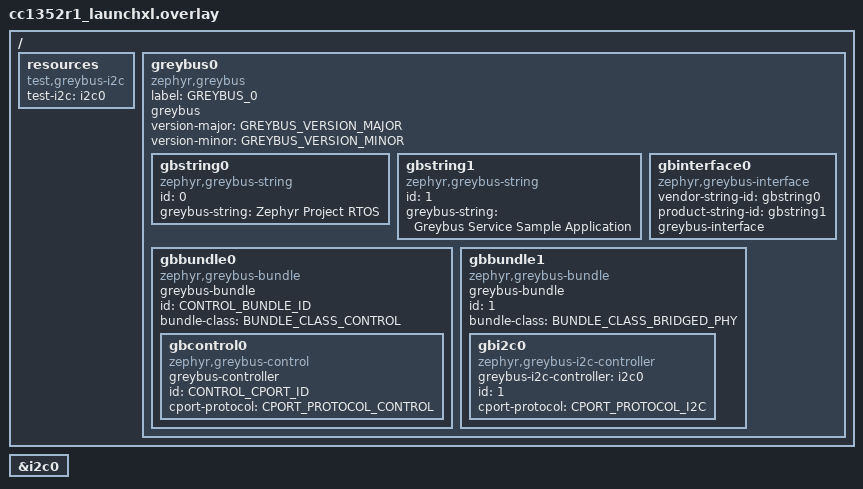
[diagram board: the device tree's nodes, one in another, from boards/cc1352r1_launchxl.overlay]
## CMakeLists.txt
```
# SPDX-License-Identifier: BSD-3-Clause

zephyr_include_directories(../../../include)

cmake_minimum_required(VERSION 3.13.1)
find_package(Zephyr REQUIRED HINTS $ENV{ZEPHYR_BASE})
project(greybus)

FILE(GLOB_RECURSE app_sources src/*.c)
target_sources(app PRIVATE ${app_sources})
```

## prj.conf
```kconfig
CONFIG_ZTEST=y

#CONFIG_REQUIRES_FULL_LIBC=y
#CONFIG_NEWLIB_LIBC=y
#CONFIG_GPIO=y
CONFIG_GREYBUS=y
#CONFIG_GB_LOG_LEVEL=4
#CONFIG_GREYBUS_AUDIO=y
#CONFIG_GREYBUS_CAMERA=y
CONFIG_GREYBUS_CONTROL=y
#CONFIG_GREYBUS_GPIO=y
#CONFIG_GREYBUS_DEBUG=y
#CONFIG_GREYBUS_HID=y
CONFIG_GREYBUS_I2C=y
#CONFIG_GREYBUS_LIGHTS=y
#CONFIG_GREYBUS_LOOPBACK=y
#CONFIG_GREYBUS_POWER_SUPPLY=y
#CONFIG_GREYBUS_PWM=y
#CONFIG_GREYBUS_SDIO=y
#CONFIG_GREYBUS_SPI=y
#CONFIG_GREYBUS_UART=y
#CONFIG_GREYBUS_USB=y
#CONFIG_GREYBUS_VIBRATOR=y
CONFIG_CONSOLE_SUBSYS=y
#CONFIG_CONSOLE_GETCHAR=y
CONFIG_NO_OPTIMIZATIONS=y
CONFIG_MINIMAL_LIBC_MALLOC_ARENA_SIZE=16384
#CONFIG_MINIMAL_LIBC_MALLOC_ARENA_SIZE=32768
# Generic networking options
CONFIG_NETWORKING=y
CONFIG_NET_UDP=y
CONFIG_NET_TCP=y
CONFIG_NET_IPV6=y
CONFIG_NET_IPV4=y
CONFIG_NET_SOCKETS=y
CONFIG_NET_SOCKETS_POSIX_NAMES=y
CONFIG_POSIX_MAX_FDS=32

# Kernel options
CONFIG_MAIN_STACK_SIZE=1024
#CONFIG_ENTROPY_GENERATOR=y
CONFIG_TEST_RANDOM_GENERATOR=y
CONFIG_INIT_STACKS=y

# Logging
CONFIG_NET_LOG=y
CONFIG_LOG=y
CONFIG_NET_STATISTICS=y
CONFIG_PRINTK=y

# Network buffers
CONFIG_NET_PKT_RX_COUNT=4
CONFIG_NET_PKT_TX_COUNT=4
CONFIG_NET_BUF_RX_COUNT=16
CONFIG_NET_BUF_TX_COUNT=16
CONFIG_NET_CONTEXT_NET_PKT_POOL=y

# IP address options
CONFIG_NET_IF_UNICAST_IPV6_ADDR_COUNT=3
CONFIG_NET_IF_MCAST_IPV6_ADDR_COUNT=4
CONFIG_NET_MAX_CONTEXTS=10

# Network shell
CONFIG_NET_SHELL=y
CONFIG_SHELL=y

# Network application options and configuration
CONFIG_NET_CONFIG_SETTINGS=y
CONFIG_NET_CONFIG_MY_IPV6_ADDR="2001:db8::1"
CONFIG_NET_CONFIG_PEER_IPV6_ADDR="2001:db8::2"
CONFIG_NET_CONFIG_MY_IPV4_ADDR="192.0.2.1"
CONFIG_NET_CONFIG_PEER_IPV4_ADDR="192.0.2.2"

# How many client can connect to echo-server simultaneously
#CONFIG_NET_SAMPLE_NUM_HANDLERS=1

# Temporary until automatic thread stack allocation is available
CONFIG_PTHREAD_DYNAMIC_STACK=y
CONFIG_PTHREAD_DYNAMIC_STACK_RESERVED_COUNT=8
```

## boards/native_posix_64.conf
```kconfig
# Copyright (c) 2020 Friedt Professional Engineering Services, Inc
# SPDX-License-Identifier: BSD-3-Clause

CONFIG_GPIO_SIM=y
```

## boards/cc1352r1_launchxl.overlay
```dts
/*
 * Copyright (c) 2020 Friedt Professional Engineering Services, Inc
 *
 * SPDX-License-Identifier: BSD-3-Clause
 */
 #include <dt-bindings/greybus/greybus.h>

/ {
	resources {
		compatible = "test,greybus-i2c";
		test-i2c = <&i2c0>; 
	};

	greybus0: greybus0 {
		compatible = "zephyr,greybus";
		label = "GREYBUS_0";
		greybus;
	};
};

&i2c0 {
	status = "okay";
};

&greybus0 {
	status = "okay";
	/* defaults in effect, so this isn't necessary */
	version-major = <GREYBUS_VERSION_MAJOR>;
	version-minor = <GREYBUS_VERSION_MINOR>;

	gbstring0: gbstring0 {
		status = "okay";
		compatible = "zephyr,greybus-string";
		id = <0>;
		greybus-string = "Zephyr Project RTOS";
	};

	gbstring1: gbstring1 {
		status = "okay";
		compatible = "zephyr,greybus-string";
		id = <1>;
		greybus-string = "Greybus Service Sample Application";
	};

	gbinterface0 {
		status = "okay";
		compatible = "zephyr,greybus-interface";
		vendor-string-id = <&gbstring0>;
		product-string-id = <&gbstring1>;
		greybus-interface;
	};

	gbbundle0 {
		status = "okay";
		compatible = "zephyr,greybus-bundle";
		greybus-bundle;
		/* Control Bundle 0
		 * Note: control bundle 0 and control cport 0 are optional
		 * Since instance numbers automatically begin at 0, the id
		 * is a mandatory field for bundles and cports.
		 */
		id = <CONTROL_BUNDLE_ID>;
		bundle-class = <BUNDLE_CLASS_CONTROL>;

		gbcontrol0 {
			status = "okay";
			compatible = "zephyr,greybus-control";
			greybus-controller;
			/* Control CPort 0
			 * Note: control bundle 0 and control cport 0 are optional
			 * Since instance numbers automatically begin at 0, the id
			 * is a mandatory field for bundles and cports.
			 */
			id = <CONTROL_CPORT_ID>;
			cport-protocol = <CPORT_PROTOCOL_CONTROL>; 
		};
	};
	
	gbbundle1 {
		status = "okay";
		compatible = "zephyr,greybus-bundle";
		greybus-bundle;
		id = <1>;
		bundle-class = <BUNDLE_CLASS_BRIDGED_PHY>;		
				
		gbi2c0 {
			status = "okay";
			compatible = "zephyr,greybus-i2c-controller";
			greybus-i2c-controller = <&i2c0>;
			id = <1>;
			cport-protocol = <CPORT_PROTOCOL_I2C>;
		};
	};
};
```

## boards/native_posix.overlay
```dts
/*
 * Copyright (c) 2020 Friedt Professional Engineering Services, Inc
 *
 * SPDX-License-Identifier: BSD-3-Clause
 */
 #include <dt-bindings/greybus/greybus.h>

/ {
	resources {
		compatible = "test,greybus-i2c";
		test-i2c = <&i2c0>; 
	};

	greybus0: greybus0 {
		compatible = "zephyr,greybus";
		label = "GREYBUS_0";
		greybus;
	};
};

&i2c0 {
	status = "okay";
};

&greybus0 {
	label = "GREYBUS_0";
	status = "okay";
	/* defaults in effect, so this isn't necessary */
	version-major = <GREYBUS_VERSION_MAJOR>;
	version-minor = <GREYBUS_VERSION_MINOR>;

	gbstring0: gbstring0 {
		label = "GBSTRING_0";
		status = "okay";
		compatible = "zephyr,greybus-string";
		id = <0>;
		greybus-string = "Zephyr Project RTOS";
	};

	gbstring1: gbstring1 {
		label = "GBSTRING_1";
		status = "okay";
		compatible = "zephyr,greybus-string";
		id = <1>;
		greybus-string = "Greybus Service Sample Application";
	};

	gbinterface0 {
		label = "GBINTERFACE_0";
		status = "okay";
		compatible = "zephyr,greybus-interface";
		vendor-string-id = <&gbstring0>;
		product-string-id = <&gbstring1>;
		greybus-interface;
	};

	gbbundle0 {
		label = "GBBUNDLE_0";
		status = "okay";
		compatible = "zephyr,greybus-bundle";
		greybus-bundle;
		/* Control Bundle 0
		 * Note: control bundle 0 and control cport 0 are optional
		 * Since instance numbers automatically begin at 0, the id
		 * is a mandatory field for bundles and cports.
		 */
		id = <CONTROL_BUNDLE_ID>;
		bundle-class = <BUNDLE_CLASS_CONTROL>;

		gbcontrol0 {
			label = "GBCONTROL_0";
			status = "okay";
			compatible = "zephyr,greybus-control";
			greybus-controller;
			/* Control CPort 0
			 * Note: control bundle 0 and control cport 0 are optional
			 * Since instance numbers automatically begin at 0, the id
			 * is a mandatory field for bundles and cports.
			 */
			id = <CONTROL_CPORT_ID>;
			cport-protocol = <CPORT_PROTOCOL_CONTROL>; 
		};
	};
	
	gbbundle1 {
		label = "GBBUNDLE_1";
		status = "okay";
		compatible = "zephyr,greybus-bundle";
		greybus-bundle;
		id = <1>;
		bundle-class = <BUNDLE_CLASS_BRIDGED_PHY>;		
				
		gbi2c0 {
			label = "GBI2C_0";
			status = "okay";
			compatible = "zephyr,greybus-i2c-controller";
			greybus-i2c-controller = <&i2c0>;
			id = <1>;
			cport-protocol = <CPORT_PROTOCOL_I2C>;
		};
	};
};
```

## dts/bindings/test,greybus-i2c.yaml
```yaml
#
# Copyright (c) 2020 Friedt Professional Engineering Services, Inc
#
# SPDX-License-Identifier: BSD-3-Clause
#

description: |
    This binding provides resources required to build and run the
    i2c-related tests under tests/subsys/greybus test in Zephyr.

compatible: "test,greybus-i2c"

properties:
    test-i2c:
        type: phandle
        required: true
        description: |
          Identity of an I2C device that will be used with Greybus.
```

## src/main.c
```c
/*
 * Copyright (c) 2020 Friedt Professional Engineering Services, Inc
 *
 * SPDX-License-Identifier: BSD-3-Clause
 */

#include <ztest.h>

extern void test_greybus_i2c_protocol_version(void);
extern void test_greybus_i2c_cport_shutdown(void);
extern void test_greybus_i2c_functionality(void);
extern void test_greybus_i2c_transfer(void);

static void board_setup(void)
{
	if (IS_ENABLED(CONFIG_I2C_SIM)) {
		extern void i2c_sim_setup(void);
		i2c_sim_setup();
	}
}

extern void test_greybus_setup(void);
extern void test_greybus_teardown(void);

void test_main(void) {

	board_setup();
	test_greybus_setup();
    ztest_test_suite(greybus_i2c,
        ztest_unit_test(test_greybus_i2c_protocol_version),
        ztest_unit_test(test_greybus_i2c_cport_shutdown),
        ztest_unit_test(test_greybus_i2c_functionality),
        ztest_unit_test(test_greybus_i2c_transfer)
        );
    ztest_run_test_suite(greybus_i2c);
    test_greybus_teardown();
}
```

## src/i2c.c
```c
/*
 * Copyright (c) 2020 Friedt Professional Engineering Services, Inc
 *
 * SPDX-License-Identifier: BSD-3-Clause
 */

#include <device.h>
#include <errno.h>
#include <greybus/greybus.h>
#include <string.h>
#include <sys/util.h>
#include <ztest.h>
#include <zephyr.h>

#if defined(CONFIG_BOARD_NATIVE_POSIX_64BIT) ||                                \
	defined(CONFIG_BOARD_NATIVE_POSIX_32BIT) ||                            \
	defined(CONFIG_BOARD_NRF52_BSIM)

#include <arpa/inet.h>
#include <netinet/in.h>
#include <poll.h>
#include <sys/byteorder.h>
#include <sys/types.h>
#include <sys/socket.h>
#include <unistd.h>

#else

#include <net/socket.h>
#include <posix/unistd.h>

#undef perror
#define perror(s) LOG_ERR("%s", s)

#endif

#include "../../../../subsys/greybus/i2c-gb.h"

#include "test-greybus-i2c.h"

#define TIMEOUT_MS 1000
#define PORT 4243

static struct device *i2c_dev;

static int fd = -1;

void test_greybus_setup(void)
{
	struct sockaddr_in6 addr = {
		.sin6_family = AF_INET6,
		.sin6_addr = in6addr_loopback,
		.sin6_port = htons(PORT),
	};
	socklen_t addrlen = sizeof(addr);
	int r;

	i2c_dev = device_get_binding(I2C_DEV_NAME);
	zassert_not_equal(i2c_dev, NULL,
			  "failed to get device binding for " I2C_DEV_NAME);

	r = socket(AF_INET6, SOCK_STREAM, 0);
	__ASSERT(r >= 0, "connect: %d", errno);
	fd = r;

	r = connect(fd, (const struct sockaddr *)&addr, addrlen);
	__ASSERT(r == 0, "connect: %d", errno);
}

void test_greybus_teardown(void)
{
	if (fd != -1) {
		close(fd);
		fd = -1;
	}
}

static void tx_rx(const struct gb_operation_hdr *req,
		  struct gb_operation_hdr *rsp, size_t rsp_size)
{
	int r;
	int size;
	struct pollfd pollfd;
	const size_t hdr_size = sizeof(struct gb_operation_hdr);

	size = sys_le16_to_cpu(req->size);
	r = send(fd, req, size, 0);
	zassert_not_equal(r, -1, "send: %s", errno);
	zassert_equal(r, size, "write: expected: %d actual: %d", size, r);

	pollfd.fd = fd;
	pollfd.events = POLLIN;

	r = poll(&pollfd, 1, TIMEOUT_MS);
	zassert_not_equal(r, -1, "poll: %s", errno);
	zassert_not_equal(r, 0, "timeout waiting for response");
	zassert_equal(r, 1, "invalid number of pollfds with data: %d", r);

	r = recv(fd, rsp, hdr_size, 0);
	zassert_not_equal(r, -1, "recv: %s", errno);
	zassert_equal(hdr_size, r, "recv: expected: %u actual: %u",
		      (unsigned)hdr_size, r);

	zassert_equal(rsp->id, req->id,
			  "expected: 0x%04x actual: 0x%04x",
			  sys_le16_to_cpu(req->id),
			  sys_le16_to_cpu(rsp->id));
	zassert_equal(rsp->type, GB_TYPE_RESPONSE_FLAG | req->type,
			  "expected: %u actual: %u",
			  GB_TYPE_RESPONSE_FLAG | req->type, rsp->type);
}

void test_greybus_i2c_protocol_version(void)
{
	const struct gb_operation_hdr req = {
		.size = sys_cpu_to_le16(sizeof(struct gb_operation_hdr)),
		.id = sys_cpu_to_le16(0xabcd),
		.type = GB_I2C_PROTOCOL_VERSION,
	};
	uint8_t rsp_[0 + sizeof(struct gb_operation_hdr) +
		     sizeof(struct gb_i2c_proto_version_response)];
	const size_t rsp_size = sizeof(rsp_);
	struct gb_i2c_proto_version_response *const rsp =
		(struct gb_i2c_proto_version_response
			 *)(rsp_ + sizeof(struct gb_operation_hdr));

	tx_rx(&req, (struct gb_operation_hdr *)rsp_, rsp_size);

	zassert_equal(((struct gb_operation_hdr *)rsp_)->result, GB_OP_SUCCESS,
		      "expected: GB_OP_SUCCESS actual: %u",
		      ((struct gb_operation_hdr *)rsp_)->result);

	/* GB_I2C_VERSION_MAJOR (0) is buried in subsys/greybus/i2c.c */
	zassert_equal(rsp->major, 0, "expected: %u actual: %u", 0, rsp->major);

	/* GB_I2C_VERSION_MINOR (1) is buried in subsys/greybus/i2c.c */
	zassert_equal(rsp->minor, 1, "expected: %u actual: %u", 1, rsp->minor);
}

void test_greybus_i2c_cport_shutdown(void)
{
	/*
	 * looks like the original NuttX implementation was missing any kind
	 * of cport shutdown request
	 */
}

void test_greybus_i2c_functionality(void)
{
	const struct gb_operation_hdr req = {
		.size = sys_cpu_to_le16(sizeof(struct gb_operation_hdr)),
		.id = sys_cpu_to_le16(0xabcd),
		.type = GB_I2C_PROTOCOL_FUNCTIONALITY,
	};
	uint8_t rsp_[0 + sizeof(struct gb_operation_hdr) +
		     sizeof(struct gb_i2c_functionality_rsp)];
	const size_t rsp_size = sizeof(rsp_);
	struct gb_i2c_functionality_rsp *const rsp =
		(struct gb_i2c_functionality_rsp
			 *)(rsp_ + sizeof(struct gb_operation_hdr));
	uint32_t expected_uint32;
	uint32_t actual_uint32;

	tx_rx(&req, (struct gb_operation_hdr *)rsp_, rsp_size);

	zassert_equal(((struct gb_operation_hdr *)rsp_)->result, GB_OP_SUCCESS,
		      "expected: GB_OP_SUCCESS actual: %u",
		      ((struct gb_operation_hdr *)rsp_)->result);

	expected_uint32 = GB_I2C_FUNC_I2C | GB_I2C_FUNC_SMBUS_READ_BYTE |
			  GB_I2C_FUNC_SMBUS_WRITE_BYTE |
			  GB_I2C_FUNC_SMBUS_READ_BYTE_DATA |
			  GB_I2C_FUNC_SMBUS_WRITE_BYTE_DATA |
			  GB_I2C_FUNC_SMBUS_READ_WORD_DATA |
			  GB_I2C_FUNC_SMBUS_WRITE_WORD_DATA |
			  GB_I2C_FUNC_SMBUS_READ_I2C_BLOCK |
			  GB_I2C_FUNC_SMBUS_WRITE_I2C_BLOCK;

	actual_uint32 = sys_le32_to_cpu(rsp->functionality);

	zassert_equal(expected_uint32, actual_uint32,
		      "functionality: expected: %08x actual: %08x",
		      expected_uint32, actual_uint32);
}

void test_greybus_i2c_transfer(void)
{
}
```

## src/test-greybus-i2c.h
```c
/*
 * Copyright (c) 2020 Friedt Professional Engineering Services, Inc
 *
 * SPDX-License-Identifier: BSD-3-Clause
 */

#ifndef TESTS_SUBSYS_TEST_GREYBUS_I2C_H_
#define TESTS_SUBSYS_TEST_GREYBUS_I2C_H_

#ifdef __cplusplus
extern "C" {
#endif

#include <zephyr.h>
#include <drivers/i2c.h>
#include <sys/util.h>
#include <ztest.h>

#if DT_NODE_HAS_STATUS(DT_INST(0, test_greybus_i2c), okay)
/* Execution of the test requires hardware configuration described in
 * devicetree.  See the test,i2c_basic_api binding local to this test
 * for details.
 *
 * If this is not present devices that have i2c-0, i2c-1, or i2c-2
 * aliases are supported for build-only tests.
 */

#ifndef DT_I2C_LABEL_BY_IDX
#define DT_I2C_LABEL_BY_IDX(node_id, i2c_pha, idx) \
		DT_PROP_BY_PHANDLE_IDX(node_id, i2c_pha, idx, label)
#endif

#ifndef DT_I2C_LABEL
#define DT_I2C_LABEL(node_id, i2c_pha) \
		DT_I2C_LABEL_BY_IDX(node_id, i2c_pha, 0)
#endif

#define I2C_DEV_NAME DT_I2C_LABEL(DT_INST(0, test_greybus_i2c), test_i2c)

#elif DT_NODE_HAS_STATUS(DT_ALIAS(i2c_0), okay)
#define I2C_DEV_NAME DT_LABEL(DT_ALIAS(i2c_0))
#elif DT_NODE_HAS_STATUS(DT_ALIAS(i2c_1), okay)
#define I2C_DEV_NAME DT_LABEL(DT_ALIAS(i2c_1))
#elif DT_NODE_HAS_STATUS(DT_ALIAS(i2c_3), okay)
#define I2C_DEV_NAME DT_LABEL(DT_ALIAS(i2c_3))
#else
#error Unsupported board
#endif

#ifdef __cplusplus
}
#endif

#endif /* TESTS_SUBSYS_TEST_GREYBUS_I2C_H_ */
```
